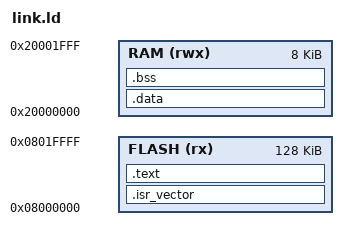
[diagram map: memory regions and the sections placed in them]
/* StardustOS - QEMU 冒烟测试链接脚本（stm32vldiscovery = STM32F100：128KB Flash / 8KB RAM） */

MEMORY
{
    FLASH (rx)  : ORIGIN = 0x08000000, LENGTH = 128K
    RAM   (rwx) : ORIGIN = 0x20000000, LENGTH = 8K
}

_estack = ORIGIN(RAM) + LENGTH(RAM);

SECTIONS
{
    .isr_vector :
    {
        . = ALIGN(4);
        KEEP(*(.isr_vector))
    } > FLASH

    .text :
    {
        . = ALIGN(4);
        *(.text*)
        *(.rodata*)
        . = ALIGN(4);
        _etext = .;
    } > FLASH

    .data : AT (_etext)
    {
        . = ALIGN(4);
        _sdata = .;
        *(.data*)
        . = ALIGN(4);
        _edata = .;
    } > RAM

    .bss :
    {
        . = ALIGN(4);
        _sbss = .;
        *(.bss*)
        *(COMMON)
        . = ALIGN(4);
        _ebss = .;
    } > RAM
}
